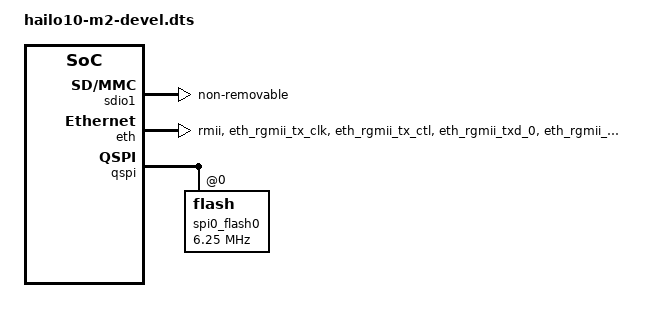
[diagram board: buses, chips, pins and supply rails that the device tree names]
// SPDX-License-Identifier:     GPL-2.0
/*
 * Copyright (c) 2019-2024 Hailo Technologies Ltd. All rights reserved.
 */

/dts-v1/;
#include "hailo10-m2.dts"

&sdio1 {
    status = "okay";
    non-removable;
    phy-config {
		card-is-emmc = <0x1>;
        	cmd-pad-values = <0x2 0x2 0x1 0x1>; // txslew_ctrl_n, txslew_ctrl_p, weakpull_enable, rxsel
        	dat-pad-values = <0x2 0x2 0x1 0x1>; // txslew_ctrl_n, txslew_ctrl_p, weakpull_enable, rxsel
        	rst-pad-values = <0x2 0x2 0x1 0x1>; // txslew_ctrl_n, txslew_ctrl_p, weakpull_enable, rxsel
        	clk-pad-values = <0x2 0x2 0x0 0x0>; // txslew_ctrl_n, txslew_ctrl_p, weakpull_enable, rxsel
        	sdclkdl-cnfg = <0x0 0x32>; //extdly_en, cckdl_dc
        	drive-strength = <0xC 0xC>; //pad_sp, pad_sn
        };
};

&eth {
    status = "okay";
    pinctrl-names = "default";
    pinctrl-0 = <&pinctrl_eth>;
    phy-mode = "rmii";
};

&qspi {
    status = "okay";
    spi0_flash0: flash@0 {
        /* values for MT25QU01G */
        spi-max-frequency = <6250000>; /* 90Mhz in DTR, 166Mhz in STR */
        cdns,read-delay = <7>;
        cdns,tshsl-ns = <30>;
        cdns,tsd2d-ns = <30>;
        cdns,tchsh-ns = <5>;
        cdns,tslch-ns = <3>;
    };
};

&pinctrl {
    pinctrl_eth: eth {
        pins = "eth_rgmii_tx_clk",
               "eth_rgmii_tx_ctl",
               "eth_rgmii_txd_0",
               "eth_rgmii_txd_1",
               "eth_rgmii_txd_2",
               "eth_rgmii_txd_3";
        drive-strength = <2>;
    };
};
